# SIM3L168_A register map
File version: 1
CPU: 
Registers are 32-bit, read-write, reset 0x0 unless marked. A register's access mark holds for its fields unless they carry their own. Offsets are from the block's base; [hi:lo] are bit positions; 'fields as' and 'values as' point back to an identical list.

## SPI_0
Base 0x40004000
Same registers: SPI_1 0x40005000
0x00 DATA read-has-side-effects — Input/Output Data
  [31:0] DATA — Input/Output Data.
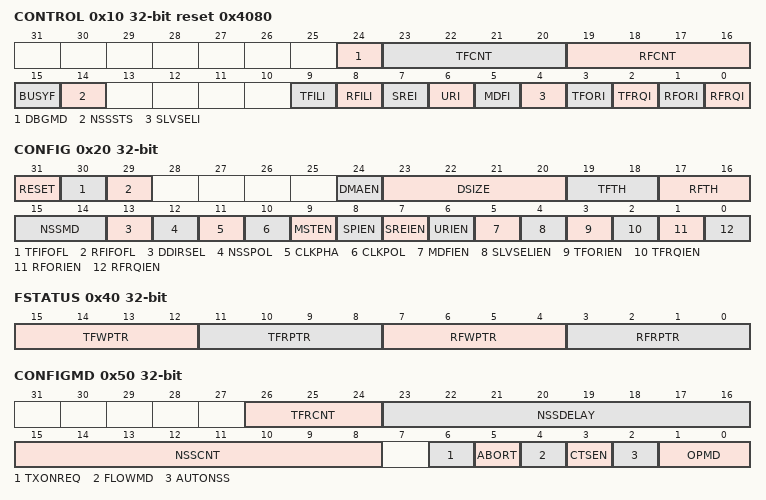
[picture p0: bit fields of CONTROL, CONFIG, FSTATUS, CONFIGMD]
0x10 CONTROL reset 0x4080 — Module Control
  [24] DBGMD — SPI Debug Mode.
    0=RUN (The SPI module will continue to operate while the core is halted in debug mode.); 1=HALT (A debug breakpoint will cause the SPI module to halt.)
  [23:20] TFCNT ro — Transmit FIFO Counter.
  [19:16] RFCNT ro — Receive FIFO Counter.
  [15] BUSYF ro — SPI Busy.
    0=NOT_SET (The SPI is not busy and a transfer is not in progress.); 1=SET (The SPI is currently busy and a transfer is in progress.)
  [14] NSSSTS ro — NSS Instantaneous Pin Status.
    0=LOW (NSS is currently a logic low.); 1=HIGH (NSS is currently a logic high.)
  [9] TFILI — Illegal Transmit FIFO Access Interrupt Flag.
    0=NOT_SET (Read: An illegal write or read of the transmit FIFO has not occurred. Write: Clear the flag.); 1=SET (Read: An illegal write or read of the transmit FIFO occurred. Write: Force an illegal transmit access interrupt.)
  [8] RFILI — Illegal Receive FIFO Access Interrupt Flag.
    0=NOT_SET (Read: An illegal write or read of the receive FIFO has not occurred. Write: Clear the flag.); 1=SET (Read: An illegal write or read of the receive FIFO occurred. Write: Force an illegal receive access interrupt.)
  [7] SREI ro — Shift Register Empty Interrupt Flag.
    0=NOT_SET (There is data still present in the transmit FIFO.); 1=SET (All data has been transferred out of the shift register and there is no data waiting in the transmit FIFO.)
  [6] URI — Underrun Interrupt Flag.
    0=NOT_SET (Read: A data transfer is still in progress. Write: Clear the flag.); 1=SET (Read: The transmit FIFO and shift register are empty and the data transfer has ended. Write: Force an underrun interrupt.)
  [5] MDFI — Mode Fault Interrupt Flag.
    0=NOT_SET (Read: A master mode collision is not detected. Write: Clear the flag.); 1=SET (Read: A master mode collision occurred. Write: Force a mode fault interrupt.)
  [4] SLVSELI ro — Slave Selected Interrupt Flag.
    0=NOT_SET (The slave select signal (NSS) is not active.); 1=SET (The slave select signal (NSS) is active.)
  [3] TFORI — Transmit FIFO Overrun Interrupt Flag.
    0=NOT_SET (Read: A transmit FIFO overrun has not occurred. Write: Clear the flag.); 1=SET (Read: A transmit FIFO overrun occurred. Write: Force a transmit overrun interrupt.)
  [2] TFRQI ro — Transmit FIFO Write Request Interrupt Flag.
    0=NOT_SET (The TX FIFO has fewer bytes than the level defined by TFTH.); 1=SET (The TX FIFO has equal or more bytes than the level defined by TFTH.)
  [1] RFORI — Receive FIFO Overrun Interrupt Flag.
    0=NOT_SET (Read: A receive FIFO overrun has not occurred. Write: Clear the flag.); 1=SET (Read: A receive FIFO overrun occurred. Write: Force a receive overrun interrupt.)
  [0] RFRQI ro — Receive FIFO Read Request Interrupt Flag.
    0=NOT_SET (The RX FIFO has fewer bytes than the level defined by RFTH.); 1=SET (The RX FIFO has equal or more bytes than the level defined by RFTH.)
0x20 CONFIG — Module Configuration
  [31] RESET — Module Soft Reset.
    0=INACTIVE (SPI module is not in soft reset.); 1=ACTIVE (SPI module is in soft reset and some of the module bits cannot be accessed until this bit is cleared to 0 by hardware.)
  [30] TFIFOFL — Transmit FIFO Flush.
    1=SET (Flush the transmit FIFO.)
  [29] RFIFOFL — Receive FIFO Flush.
    1=SET (Flush the receive FIFO.)
  [24] DMAEN — DMA Enable.
    0=DISABLED (Disable DMA requests.); 1=ENABLED (Enable DMA requests when the transmit buffer is empty or the receive buffer is full.)
  [23:20] DSIZE — Data Size.
  [19:18] TFTH — Transmit FIFO Threshold.
    0=ONE (A DMA / TFRQ request asserts when >= 1 FIFO slot is empty.); 1=TWO (A DMA / TFRQ request asserts when >= 2 FIFO slots are empty.); 2=FOUR (A DMA / TFRQ request asserts when >= 4 FIFO slots are empty.); 3=EMPTY (A DMA / TFRQ request asserts when all FIFO slots are empty.)
  [17:16] RFTH — Receive FIFO Threshold.
    0=ONE (A DMA / RFRQ request asserts when >= 1 FIFO slot is filled.); 1=TWO (A DMA / RFRQ request asserts when >= 2 FIFO slots are filled.); 2=FOUR (A DMA / RFRQ request asserts when >= 4 FIFO slots are filled.); 3=FULL (A DMA / RFRQ request asserts when all FIFO slots are filled.)
  [15:14] NSSMD — Slave Select Mode.
    0=3_WIRE_MASTER_SLAVE (3-wire Slave or 3-wire Master.); 1=4_WIRE_SLAVE (4-wire slave (NSS input). This setting can also be used for multi-master configurations.); 2=4_WIRE_MASTER_NSS_LOW (4-wire master with NSS low (NSS output).); 3=4_WIRE_MASTER_NSS_HIGH (4-wire master with NSS high (NSS output).)
  [13] DDIRSEL — Data Direction Select.
    0=MSB_FIRST (Data will be shifted MSB first.); 1=LSB_FIRST (Data will be shifted LSB first.)
  [12] NSSPOL — Slave Select Polarity Select.
    0=LOW (NSS is active low.); 1=HIGH (NSS is active high.)
  [11] CLKPHA — SPI Clock Phase.
    0=CENTER (The first edge of SCK is the sample edge (center of data bit).); 1=EDGE (The first edge of SCK is the shift edge (edge of data bit).)
  [10] CLKPOL — SPI Clock Polarity.
    0=LOW (The SCK line is low in the idle state.); 1=HIGH (The SCK line is high in the idle state.)
  [9] MSTEN — Master Mode Enable.
    0=DISABLED (Operate in slave mode.); 1=ENABLED (Operate in master mode.)
  [8] SPIEN — SPI Enable.
    0=DISABLED (Disable the SPI.); 1=ENABLED (Enable the SPI.)
  [7] SREIEN — Shift Register Empty Interrupt Enable.
    0=DISABLED (Disable the shift register empty interrupt.); 1=ENABLED (Enable the shift register empty interrupt.)
  [6] URIEN — Underrun Interrupt Enable.
    0=DISABLED (Disable the underrun interrupt.); 1=ENABLED (Enable the underrun interrupt.)
  [5] MDFIEN — Mode Fault Interrupt Enable.
    0=DISABLED (Disable the mode fault interrupt.); 1=ENABLED (Enable the mode fault interrupt.)
  [4] SLVSELIEN — Slave Selected Interrupt Enable.
    0=DISABLED (Disable the slave select interrupt.); 1=ENABLED (Enable the slave select interrupt.)
  [3] TFORIEN — Transmit FIFO Overrun Interrupt Enable.
    0=DISABLED (Disable the transmit FIFO overrun interrupt.); 1=ENABLED (Enable the transmit FIFO overrun interrupt.)
  [2] TFRQIEN — Transmit FIFO Write Request Interrupt Enable.
    0=DISABLED (Disable the transmit FIFO data request interrupt.); 1=ENABLED (Enable the transmit FIFO data request interrupt.)
  [1] RFORIEN — Receive FIFO Overrun Interrupt Enable.
    0=DISABLED (Disable the receive FIFO overrun interrupt.); 1=ENABLED (Enable the receive FIFO overrun interrupt.)
  [0] RFRQIEN — Receive FIFO Read Request Interrupt Enable.
    0=DISABLED (Disable the receive FIFO request interrupt.); 1=ENABLED (Enable the receive FIFO request interrupt.)
0x30 CLKRATE — Module Clock Rate Control
  [15:0] CLKDIV — Clock Divider.
0x40 FSTATUS — FIFO Status
  [15:12] TFWPTR ro — Transmit FIFO Write Pointer.
  [11:8] TFRPTR ro — Transmit FIFO Read Pointer.
  [7:4] RFWPTR ro — Receive FIFO Write Pointer.
  [3:0] RFRPTR ro — Receive FIFO Read Pointer.
0x50 CONFIGMD — Mode Configuration
  [26:24] TFRCNT — Transfer Count.
    0=AUTO (the apb_pbyte_en[3:0] signals determine the number of bytes to push/pop); 1=TRANSFER1 (A single byte is written/read to/from the TX/RX Fifo.); 2=TRANSFER2 (If apb_pbyte_en[3:0] equals 1 (less than apbw, which is 1), a single byte is written/read to/from the TX/RX Fifo. If apb_pbyte_en[3:0] > 1, two bytes are written/read to/from the TX/RX fifos.); 3=TRANSFER3 (If apb_pbyte_en[3:0] > 2, three bytes are written/read to/from the TX/RX fifos.nIf apb_pbyte_en[3:0] = 2, two bytes are written/read to/from the TX/RX fifos.nIf apb_pbyte_en[3:0] = 1, a single byte is written/read to/from the TX/RX fifos.); 4=TRANSFER4 (If apb_pbyte_en[3:0] = 1, a single byte is written/read to/from the TX/RX fifos.nElse, If apb_pbyte_en[3:0] = 2, two bytes are written/read to/from the TX/RX fifos.nElse, If apb_pbyte_en[3:0] = 3, three bytes are written/read to/from the TX/RX fifos.nElse, four bytes are written/read to/from the TX/RX fifos.)
  [23:16] NSSDELAY
  [15:8] NSSCNT — NSS Data Count.
  [6] TXONREQ — Transmit On Request.
    0=DISABLED (Data upon request mode is disabled); 1=ENABLED (Data upon request mode is enabled. See the "Metron32 modifications" section for details)
  [5] ABORT — Software Abort.
    0=DISABLED (No abort); 1=ENABLED (At the end of the current datum, abort, reset the SPIEN bit and reset this bit (SPI_SOFT_DIS).)
  [4] FLOWMD — Flow Control Mode.
    0=DISABLED (See the "Metron32 modifications" section for details); 1=ENABLED (See the "Metron32 modifications" section for details)
  [3] CTSEN — CTS Flow Control Enable.
    values as FLOWMD
  [2] AUTONSS — Auto NSS Mode.
    values as FLOWMD
  [1:0] OPMD — Operation Mode.
    0=NORMAL (Normal mode); 1=RECEIVE (Receive only mode. See the "Metron32 modifications" section for details); 2=TRANSMIT (Transmit only -- none of the incoming data is stored in the RX FIFO. See the "Metron32 modifications" section for details); 3=FLOWCONTROL (Flow control mode - See the "Metron32 modifications" section for details)
